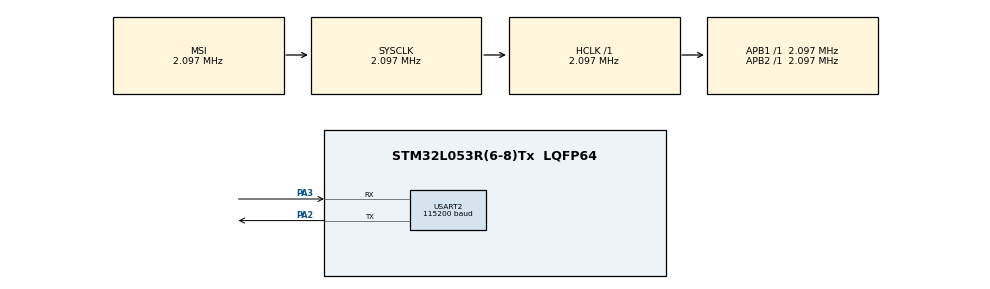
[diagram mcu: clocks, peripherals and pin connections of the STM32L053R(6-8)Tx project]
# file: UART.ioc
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Mcu.Family=STM32L0
Mcu.Name=STM32L053R(6-8)Tx
Mcu.Package=LQFP64
NVIC.USART2_IRQn=true\:0\:0\:false\:false\:true\:true\:true
PA2.Mode=Asynchronous
PA2.Signal=USART2_TX
PA3.Mode=Asynchronous
PA3.Signal=USART2_RX
ProjectManager.HeapSize=0x200
ProjectManager.StackSize=0x400
ProjectManager.TargetToolchain=STM32CubeIDE
RCC.AHBFreq_Value=2097000
RCC.APB1Freq_Value=2097000
RCC.APB1TimFreq_Value=2097000
RCC.APB2Freq_Value=2097000
RCC.APB2TimFreq_Value=2097000
RCC.HSE_VALUE=8000000
RCC.HSI16_VALUE=16000000
RCC.HSI48_VALUE=48000000
RCC.HSI_VALUE=16000000
RCC.LSE_VALUE=32768
RCC.MSI_VALUE=2097000
RCC.SYSCLKFreq_VALUE=2097000
RCC.VCOOutputFreq_Value=48000000
USART2.BaudRate=115200
USART2.VirtualMode-Asynchronous=VM_ASYNC
board=custom

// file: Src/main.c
/* USER CODE BEGIN Header */
/**
  ******************************************************************************
  * @file           : main.c
  * @brief          : Main program body
  ******************************************************************************
  * @attention
  *
  * <h2><center>&copy; Copyright (c) 2020 STMicroelectronics.
  * All rights reserved.</center></h2>
  *
  * This software component is licensed by ST under BSD 3-Clause license,
  * the "License"; You may not use this file except in compliance with the
  * License. You may obtain a copy of the License at:
  *                        opensource.org/licenses/BSD-3-Clause
  *
  ******************************************************************************
  */
/* USER CODE END Header */

#include "main.h"

/* USER CODE BEGIN Includes */
#include <string.h>
/* USER CODE END Includes */

UART_HandleTypeDef huart2;

/* USER CODE BEGIN PV */
uint8_t c=0x32;
char *buffer="Hello world!\n\r";
char input[4];
/* USER CODE END PV */

void SystemClock_Config(void);
static void MX_GPIO_Init(void);
static void MX_USART2_UART_Init(void);

int main(void)
{

  /* MCU Configuration--------------------------------------------------------*/

  /* Reset of all peripherals, Initializes the Flash interface and the Systick. */
  HAL_Init();

  /* Configure the system clock */
  SystemClock_Config();

  /* Initialize all configured peripherals */
  MX_GPIO_Init();
  MX_USART2_UART_Init();
  /* USER CODE BEGIN 2 */
  __HAL_UART_ENABLE_IT(&huart2, UART_IT_TC);
  HAL_UART_Transmit_IT(&huart2, (uint8_t *) "Enter a 3 letter word: ", strlen("Enter a 3 letter word: "));
  // HAL_UART_Receive_IT(&huart2, (uint8_t *) input, 4);
  /* USER CODE END 2 */

  /* Infinite loop */
  while (1)
  {

    /* USER CODE BEGIN 3 */
	  // HAL_UART_Transmit(&huart2, (uint8_t *) buffer, 15, 10);
	  // HAL_UART_Transmit_IT(&huart2, (uint8_t *) buffer, 14);
	  // HAL_UART_Receive(&huart2, (uint8_t *) input, 4, 10000);
	  HAL_UART_Receive_IT(&huart2, (uint8_t *) input, 3);
	  input[3] = '\0';
	  if(strlen(input) == 3){
		  HAL_UART_Transmit_IT(&huart2, (uint8_t *) "\n\rYou typed: ", strlen("\n\rYou typed: "));
		  HAL_Delay(20);
		  HAL_UART_Transmit_IT(&huart2, (uint8_t *) input, 3);
		  HAL_Delay(20);
		  HAL_UART_Transmit_IT(&huart2, (uint8_t *) "\n\r", strlen("\n\r"));
		  HAL_Delay(20);
		  HAL_UART_Transmit_IT(&huart2, (uint8_t *) "Enter a 3 letter word: ", strlen("Enter a 3 letter word: "));
		  input[0] = '\0';
		  input[1] = '\0';
		  input[2] = '\0';
	  }
	  //HAL_Delay(5000);
  }
  /* USER CODE END 3 */
}

void SystemClock_Config(void)
{
  RCC_OscInitTypeDef RCC_OscInitStruct = {0};
  RCC_ClkInitTypeDef RCC_ClkInitStruct = {0};
  RCC_PeriphCLKInitTypeDef PeriphClkInit = {0};

  /** Configure the main internal regulator output voltage
  */
  __HAL_PWR_VOLTAGESCALING_CONFIG(PWR_REGULATOR_VOLTAGE_SCALE1);
  /** Initializes the CPU, AHB and APB busses clocks
  */
  RCC_OscInitStruct.OscillatorType = RCC_OSCILLATORTYPE_MSI;
  RCC_OscInitStruct.MSIState = RCC_MSI_ON;
  RCC_OscInitStruct.MSICalibrationValue = 0;
  RCC_OscInitStruct.MSIClockRange = RCC_MSIRANGE_5;
  RCC_OscInitStruct.PLL.PLLState = RCC_PLL_NONE;
  if (HAL_RCC_OscConfig(&RCC_OscInitStruct) != HAL_OK)
  {
    Error_Handler();
  }
  /** Initializes the CPU, AHB and APB busses clocks
  */
  RCC_ClkInitStruct.ClockType = RCC_CLOCKTYPE_HCLK|RCC_CLOCKTYPE_SYSCLK
                              |RCC_CLOCKTYPE_PCLK1|RCC_CLOCKTYPE_PCLK2;
  RCC_ClkInitStruct.SYSCLKSource = RCC_SYSCLKSOURCE_MSI;
  RCC_ClkInitStruct.AHBCLKDivider = RCC_SYSCLK_DIV1;
  RCC_ClkInitStruct.APB1CLKDivider = RCC_HCLK_DIV1;
  RCC_ClkInitStruct.APB2CLKDivider = RCC_HCLK_DIV1;

  if (HAL_RCC_ClockConfig(&RCC_ClkInitStruct, FLASH_LATENCY_0) != HAL_OK)
  {
    Error_Handler();
  }
  PeriphClkInit.PeriphClockSelection = RCC_PERIPHCLK_USART2;
  PeriphClkInit.Usart2ClockSelection = RCC_USART2CLKSOURCE_PCLK1;
  if (HAL_RCCEx_PeriphCLKConfig(&PeriphClkInit) != HAL_OK)
  {
    Error_Handler();
  }
}

static void MX_USART2_UART_Init(void)
{

  huart2.Instance = USART2;
  huart2.Init.BaudRate = 115200;
  huart2.Init.WordLength = UART_WORDLENGTH_8B;
  huart2.Init.StopBits = UART_STOPBITS_1;
  huart2.Init.Parity = UART_PARITY_NONE;
  huart2.Init.Mode = UART_MODE_TX_RX;
  huart2.Init.HwFlowCtl = UART_HWCONTROL_NONE;
  huart2.Init.OverSampling = UART_OVERSAMPLING_16;
  huart2.Init.OneBitSampling = UART_ONE_BIT_SAMPLE_DISABLE;
  huart2.AdvancedInit.AdvFeatureInit = UART_ADVFEATURE_NO_INIT;
  if (HAL_UART_Init(&huart2) != HAL_OK)
  {
    Error_Handler();
  }

}

static void MX_GPIO_Init(void)
{

  /* GPIO Ports Clock Enable */
  __HAL_RCC_GPIOA_CLK_ENABLE();

}

void Error_Handler(void)
{
}

/************************ (C) COPYRIGHT STMicroelectronics *****END OF FILE****/
